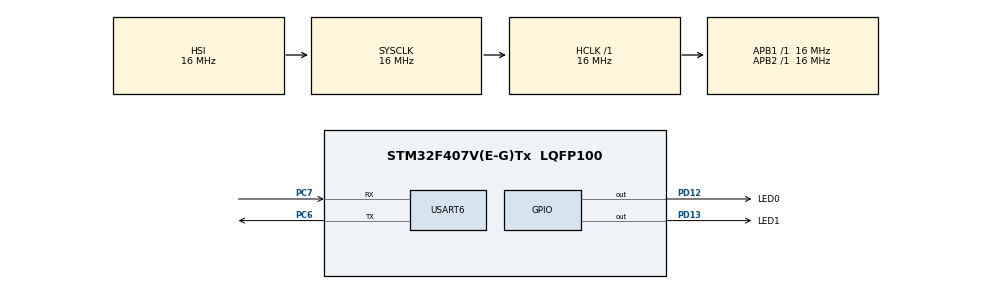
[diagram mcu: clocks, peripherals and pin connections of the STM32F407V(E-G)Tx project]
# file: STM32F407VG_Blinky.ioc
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Mcu.Family=STM32F4
Mcu.Name=STM32F407V(E-G)Tx
Mcu.Package=LQFP100
NVIC.PriorityGroup=NVIC_PRIORITYGROUP_4
PA13.Mode=Serial_Wire
PA13.Signal=SYS_JTMS-SWDIO
PA14.Mode=Serial_Wire
PA14.Signal=SYS_JTCK-SWCLK
PC6.Mode=Asynchronous
PC6.Signal=USART6_TX
PC7.Mode=Asynchronous
PC7.Signal=USART6_RX
PD12.GPIO_Label=LED0
PD12.Signal=GPIO_Output
PD13.GPIO_Label=LED1
PD13.Signal=GPIO_Output
ProjectManager.HeapSize=0x200
ProjectManager.StackSize=0x400
ProjectManager.TargetToolchain=STM32CubeIDE
RCC.AHBFreq_Value=16000000
RCC.APB1Freq_Value=16000000
RCC.APB2Freq_Value=16000000
RCC.CortexFreq_Value=16000000
RCC.HSE_VALUE=25000000
RCC.HSI_VALUE=16000000
RCC.LSE_VALUE=32768
RCC.SYSCLKFreq_VALUE=16000000
RCC.VCOOutputFreq_Value=192000000
USART6.VirtualMode=VM_ASYNC
board=custom

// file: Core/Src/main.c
/* USER CODE BEGIN Header */
/**
  ******************************************************************************
  * @file           : main.c
  * @brief          : Main program body
  ******************************************************************************
  * @attention
  *
  * <h2><center>&copy; Copyright (c) 2020 STMicroelectronics.
  * All rights reserved.</center></h2>
  *
  * This software component is licensed by ST under BSD 3-Clause license,
  * the "License"; You may not use this file except in compliance with the
  * License. You may obtain a copy of the License at:
  *                        opensource.org/licenses/BSD-3-Clause
  *
  ******************************************************************************
  */
/* USER CODE END Header */

#include "main.h"

UART_HandleTypeDef huart6;

void SystemClock_Config(void);
static void MX_GPIO_Init(void);
static void MX_USART6_UART_Init(void);

int main(void)
{

  /* MCU Configuration--------------------------------------------------------*/

  /* Reset of all peripherals, Initializes the Flash interface and the Systick. */
  HAL_Init();

  /* Configure the system clock */
  SystemClock_Config();

  /* Initialize all configured peripherals */
  MX_GPIO_Init();
  MX_USART6_UART_Init();
  /* USER CODE BEGIN 2 */
#if(FLASH_BASE != 0x08008000UL)
#error "bootloader is enable, must adjust FLASH_BASE in stm32f401xe.h"\
       "also update linker script STM32F401RETX_FLASH.ld accordingly "\
       "0x08008000UL for 32K of bootloader size"\
       "0x08004000UL for 16K of bootloader size"
#endif

  /** enable interrupts, bootloader might disable interrupts before jump */
  __enable_irq();

  __HAL_RCC_BKPSRAM_CLK_ENABLE();

  for(uint8_t i=0; i<10; i++)
      {
      HAL_GPIO_TogglePin(LED0_GPIO_Port, LED0_Pin);
      HAL_Delay(100);
      }

  __HAL_RCC_PWR_CLK_ENABLE();
  HAL_PWR_EnableBkUpAccess();

  /** bootloader magic number */
  *(__IO uint8_t *)0x40024000 = 0xA5;

  //HAL_NVIC_SystemReset();

  /* USER CODE END 2 */

  /* Infinite loop */
  while (1)
  {

  }
}

void SystemClock_Config(void)
{
  RCC_OscInitTypeDef RCC_OscInitStruct = {0};
  RCC_ClkInitTypeDef RCC_ClkInitStruct = {0};

  /** Configure the main internal regulator output voltage
  */
  __HAL_RCC_PWR_CLK_ENABLE();
  __HAL_PWR_VOLTAGESCALING_CONFIG(PWR_REGULATOR_VOLTAGE_SCALE1);
  /** Initializes the CPU, AHB and APB busses clocks
  */
  RCC_OscInitStruct.OscillatorType = RCC_OSCILLATORTYPE_HSI;
  RCC_OscInitStruct.HSIState = RCC_HSI_ON;
  RCC_OscInitStruct.HSICalibrationValue = RCC_HSICALIBRATION_DEFAULT;
  RCC_OscInitStruct.PLL.PLLState = RCC_PLL_NONE;
  if (HAL_RCC_OscConfig(&RCC_OscInitStruct) != HAL_OK)
  {
    Error_Handler();
  }
  /** Initializes the CPU, AHB and APB busses clocks
  */
  RCC_ClkInitStruct.ClockType = RCC_CLOCKTYPE_HCLK|RCC_CLOCKTYPE_SYSCLK
                              |RCC_CLOCKTYPE_PCLK1|RCC_CLOCKTYPE_PCLK2;
  RCC_ClkInitStruct.SYSCLKSource = RCC_SYSCLKSOURCE_HSI;
  RCC_ClkInitStruct.AHBCLKDivider = RCC_SYSCLK_DIV1;
  RCC_ClkInitStruct.APB1CLKDivider = RCC_HCLK_DIV1;
  RCC_ClkInitStruct.APB2CLKDivider = RCC_HCLK_DIV1;

  if (HAL_RCC_ClockConfig(&RCC_ClkInitStruct, FLASH_LATENCY_0) != HAL_OK)
  {
    Error_Handler();
  }
}

static void MX_USART6_UART_Init(void)
{

  huart6.Instance = USART6;
  huart6.Init.BaudRate = 115200;
  huart6.Init.WordLength = UART_WORDLENGTH_8B;
  huart6.Init.StopBits = UART_STOPBITS_1;
  huart6.Init.Parity = UART_PARITY_NONE;
  huart6.Init.Mode = UART_MODE_TX_RX;
  huart6.Init.HwFlowCtl = UART_HWCONTROL_NONE;
  huart6.Init.OverSampling = UART_OVERSAMPLING_16;
  if (HAL_UART_Init(&huart6) != HAL_OK)
  {
    Error_Handler();
  }

}

static void MX_GPIO_Init(void)
{
  GPIO_InitTypeDef GPIO_InitStruct = {0};

  /* GPIO Ports Clock Enable */
  __HAL_RCC_GPIOD_CLK_ENABLE();
  __HAL_RCC_GPIOC_CLK_ENABLE();
  __HAL_RCC_GPIOA_CLK_ENABLE();

  /*Configure GPIO pin Output Level */
  HAL_GPIO_WritePin(GPIOD, LED0_Pin|LED1_Pin, GPIO_PIN_RESET);

  /*Configure GPIO pins : LED0_Pin LED1_Pin */
  GPIO_InitStruct.Pin = LED0_Pin|LED1_Pin;
  GPIO_InitStruct.Mode = GPIO_MODE_OUTPUT_PP;
  GPIO_InitStruct.Pull = GPIO_NOPULL;
  GPIO_InitStruct.Speed = GPIO_SPEED_FREQ_LOW;
  HAL_GPIO_Init(GPIOD, &GPIO_InitStruct);

}

void Error_Handler(void)
{
}

/************************ (C) COPYRIGHT STMicroelectronics *****END OF FILE****/
